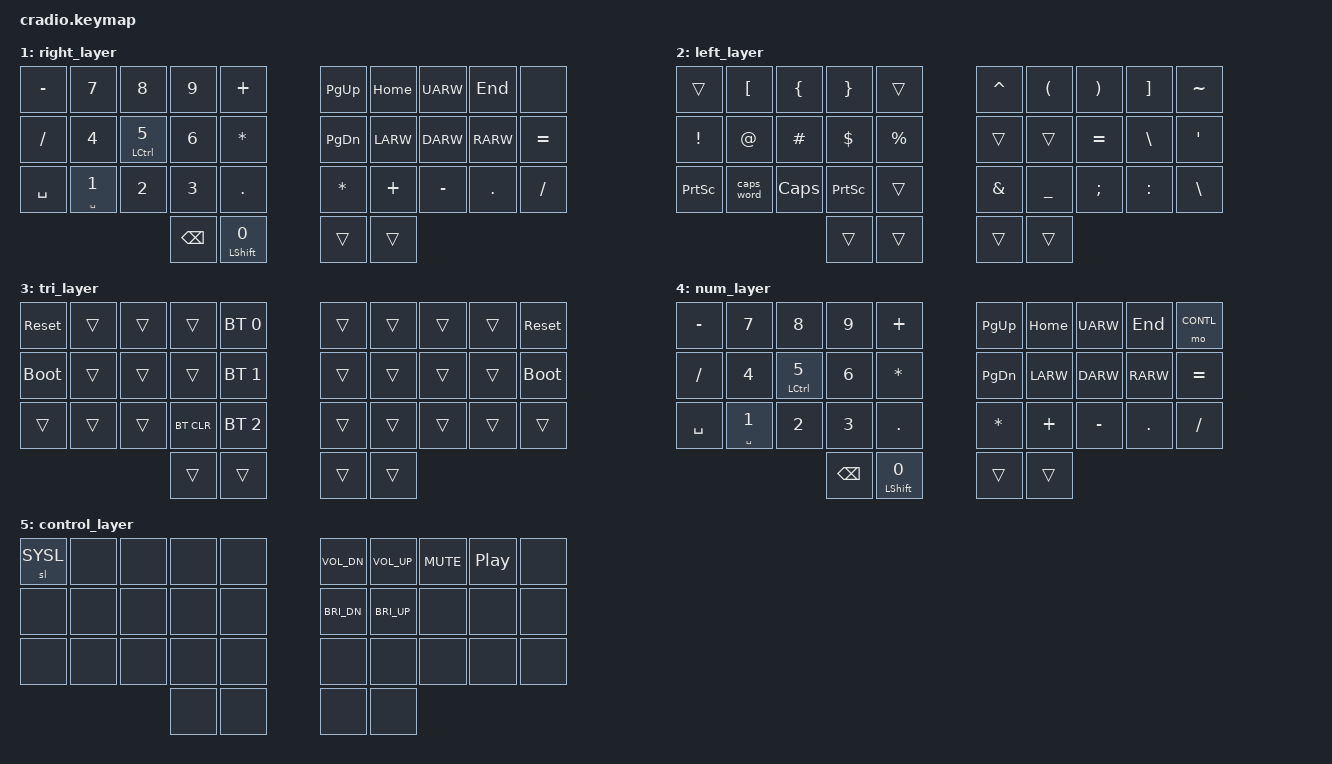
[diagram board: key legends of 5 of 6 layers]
// Copyright (c) 2022 The ZMK Contributors
// SPDX-License-Identifier: MIT

#include <behaviors.dtsi>
#include <dt-bindings/zmk/keys.h>
#include <dt-bindings/zmk/bt.h>

#include "../config/keypos_34keys.h"

#define DEFAULT 0
#define RIGHTL  1
#define LEFTL   2
#define SYSL    3
#define NUML    4
#define CONTL   5



// Home row mods macro
#define HRML(k1,k2,k3) &ht LALT k1  &ht LCTRL k2  &ht LGUI k3
#define HRMR(k1,k2,k3) &ht RGUI k1  &ht RCTRL k2  &ht RALT k3


&sk {  // sticky-key config
    release-after-ms = <600>;  // release after 0.6s
    quick-release;             // no double capitalization when rolling keys
};


/ {

    behaviors {
        ht: hold_tap {
            label = "hold_tap";
            compatible = "zmk,behavior-hold-tap";
            #binding-cells = <2>;
            flavor = "balanced";
            tapping-term-ms = <220>;
            quick-tap-ms = <150>;
            global-quick-tap;
            bindings = <&kp>, <&kp>;
        };
        pt: punctuation_tap {
            label = "punctuation_tap";
            compatible = "zmk,behavior-hold-tap";
            #binding-cells = <2>;
            flavor = "tap-preferred";
            tapping-term-ms = <180>;
            bindings = <&kp>, <&kp>;
        };


        ltt: layer_tap_with_rolling {
            label = "layer_tap_with_rolling";
            compatible = "zmk,behavior-hold-tap";
            #binding-cells = <2>;
            flavor = "tap-preferred";
            tapping-term-ms = <200>;
            quick-tap-ms = <125>;
            global-quick-tap;
            bindings = <&mo>, <&kp>;
        };


//      stt: sticky_tap {
//          label = "sticky_tap";
//          compatible = "zmk,behavior-hold-tap";
//          #binding-cells = <2>;
//          flavor = "hold-preferred";
//          tapping-term-ms = <90>;
//          bindings = <&kp>, <&sk>;
//      };
        swt: tab_switching {
            compatible = "zmk,behavior-mod-morph";
            label = "TAB_SWITCHING";
            #binding-cells = <0>;
            bindings = <&lt LEFTL BSPC>, <&kp TAB>;
            mods = <(MOD_LCTL|MOD_LALT)>;
            keep-mods = <(MOD_LCTL|MOD_LALT)>;
        };

    };

/*
    conditional_layers {
        compatible = "zmk,conditional-layers";
        tri_layer {
            if-layers = <RIGHTL LEFTL>;
            then-layer = <SYSL>;
        };
    };
*/
    
    
//  key position reference
//  ╭─────────────────────┬─────────────────────╮
//  │ LT4 LT3 LT2 LT1 LT0 │ RT0 RT1 RT2 RT3 RT4 │
//  │ LM4 LM3 LM2 LM1 LM0 │ RM0 RM1 RM2 RM3 RM4 │
//  │ LB4 LB3 LB2 LB1 LB0 │ RB0 RB1 RB2 RB3 RB4 │
//  ╰───────────╮ LH1 LH0 │ RH0 RH1 ╭───────────╯
//              ╰─────────┴─────────╯

     combos {
        compatible = "zmk,combos";
        
        combo_esc {
            timeout-ms = <50>;
            key-positions = <LT4 LT3>;
            bindings = <&kp ESC>;
        };
        combo_del {
            timeout-ms = <50>;
            key-positions = <LT3 LT2>;
            bindings = <&kp DEL>;
            layers = <DEFAULT NUML>;
        };
        combo_tab {
            timeout-ms = <45>;
            key-positions = <LM4 LM3>;
            bindings = <&kp TAB>;
            layers = <DEFAULT NUML RIGHTL>;
        };
         combo_enter_r {
            timeout-ms = <35>;
            key-positions = <RM2 RM3>;
            bindings = <&kp ENTER>;
        };
         combo_enter_l {
            timeout-ms = <35>;
            key-positions = <LM2 LM3>;
            bindings = <&ht LC(S) ENTER>;
        };
        combo_word_backspace {
            timeout-ms = <75>;
            key-positions = <LH1 RH1>;
            bindings = <&macro_word_bsp>;
            layers = <DEFAULT NUML>;
        };
        combo_word_delete {
            timeout-ms = <50>;
            key-positions = <LH0 RH0>;
            bindings = <&kp LC(DEL)>;
            layers = <DEFAULT>;
        };
        combo_equal {
            timeout-ms = <50>;
            key-positions = <LT0 LT1>;
            bindings = <&kp EQUAL>;
            layers = <RIGHTL NUML>;
        };
        combo_quote {
            timeout-ms = <50>;
            key-positions = <LB0 LB1>;
            bindings = <&kp DQT>;
            layers = <RIGHTL NUML>;
        };
        combo_num_layer {
            timeout-ms = <50>;
            key-positions = <LM1 LM3>;
            bindings = <&tog NUML>;
            layers = <DEFAULT NUML>;
        };
        combo_ctrl_f {
            timeout-ms = <50>;
            key-positions = <LT2 LM2>;
            bindings = <&kp LC(F)>;
            layers = <DEFAULT NUML>;
        };
        combo_at {
            timeout-ms = <35>;
            key-positions = <LM4 LM1>;
            bindings = <&kp AT>;
            layers = <DEFAULT RIGHTL NUML>;
        };
        combo_next_tab {
            timeout-ms = <40>;
            key-positions = <LB2 LB1>;
            bindings = <&kp LC(TAB)>;
            layers = <DEFAULT>;
        };
        combo_previous_tab {
            timeout-ms = <40>;
            key-positions = <LB3 LB2>;
            bindings = <&kp LC(LS(TAB))>;
            layers = <DEFAULT>;
        };
        combo_ctrl_x {
            timeout-ms = <50>;
            key-positions = <LT0 LT1>;
            bindings = <&kp LC(X)>;
            layers = <DEFAULT>;
        };
        combo_ctrl_c {
            timeout-ms = <50>;
            key-positions = <LM0 LM1>;
            bindings = <&kp LC(C)>;
            layers = <DEFAULT>;
        };
        combo_ctrl_v {
            timeout-ms = <50>;
            key-positions = <LB0 LB1>;
            bindings = <&kp LC(V)>;
            layers = <DEFAULT>;
        };

    };


    macros {
        macro_word_bsp: macro_word_bsp {
            label = "ZM_macro_word_backspace";
            compatible = "zmk,behavior-macro";
            #binding-cells = <0>;
            bindings
                = <&kp LS(LC(LARW))>
                , <&kp BSPC>
                ;
        };
    };
    
    keymap {
        compatible = "zmk,keymap";
        default_layer {
            bindings = <
        //╭──────────┬──────────┬──────────┬──────────┬──────────╮   ╭──────────┬──────────┬──────────┬──────────┬──────────╮
        //│  Q       │  W       │  F       │  P       │  G       │   │  J       │  L       │  U       │  Y       │  '       │
            &kp Q      &kp W      &kp F      &kp P      &kp G          &kp J      &kp L      &kp U      &kp Y      &ltt CONTL APOS
        //├──────────┼──────────┼──────────┼──────────┼──────────┤   ├──────────┼──────────┼──────────┼──────────┼──────────┤
        //│  A       │  R       │  S       │  T       │  D       │   │  H       │  N       │  E       │  I       │  O       │
            &kp A      HRML(R,         S,         T)     &kp D         &kp H      HRMR(N,        E,         I)     &kp O
        //├──────────┼──────────┼──────────┼──────────┼──────────┤   ├──────────┼──────────┼──────────┼──────────┼──────────┤
        //│  Z       │  X       │  C       │  V       │  B       │   │  K       │  M       │ ,        │ .        │ / ?      │
            &kp Z      &pt Z X    &kp C      &kp V      &kp B          &kp K      &kp M      &kp COMMA  &kp DOT    &pt EXCL FSLH
        //╰──────────┴──────────┴──────────┼──────────┼──────────┤   ├──────────┼──────────┼──────────┴──────────┴──────────╯
        //                                 |          |          |   |          |          |
                                             &swt       &kp LSHIFT     &key_repeat &lt RIGHTL SPACE
        //                                 ╰──────────┴──────────╯   ╰──────────┴──────────╯
            >;
        };

        right_layer {
            bindings = <
        //╭──────────┬──────────┬──────────┬──────────┬──────────╮   ╭──────────┬──────────┬──────────┬──────────┬──────────╮
        //│ -        │  7       │  8       │  9       │  +       │   │ PAGE UP  │  HOME    │  UP      │ END      │          │
            &kp MINUS  &kp N7     &kp N8     &kp N9     &kp PLUS       &kp PG_UP  &kp HOME   &kp UARW   &kp END    &none
        //├──────────┼──────────┼──────────┼──────────┼──────────┤   ├──────────┼──────────┼──────────┼──────────┼──────────┤
        //│ /        │  4       │  5       │  6       │  *       │   │ PAGE DN  │ LEFT     │ DOWN     │ RIGHT    │  =       │
            &kp FSLH   &kp N4  &ht LCTRL N5  &kp N6     &kp ASTRK      &kp PG_DN  &kp LARW   &kp DARW   &kp RARW   &kp EQUAL
        //├──────────┼──────────┼──────────┼──────────┼──────────┤   ├──────────┼──────────┼──────────┼──────────┼──────────┤
        //│          │  1       │  2       │  3       │  .       │   │ *        │  +       │  -       │  .       │  /       │
          &kp SPACE  &pt SPACE N1 &kp N2     &kp N3     &kp DOT        &kp ASTRK  &kp PLUS   &kp MINUS  &kp DOT    &kp SLASH
        //╰──────────┴──────────┴──────────┼──────────┼──────────┤   ├──────────┼──────────┼──────────┴──────────┴──────────╯
        //                                 |          |  0       |   |          |          |
                                             &kp BSPC   &ht LSHIFT N0  &trans     &trans
        //                                 ╰──────────┴──────────╯   ╰──────────┴──────────╯
            >;
        };

        left_layer {
            bindings = <
        //╭──────────┬──────────┬──────────┬──────────┬──────────╮   ╭──────────┬──────────┬──────────┬──────────┬──────────╮
        //│          │  [       │  {       │  }       │          │   │  ^       │  (       │  )       │  ]       │  ~       │
            &trans     &kp LBKT   &kp LBRC   &kp RBRC   &trans         &kp CARET  &kp LPAR   &kp RPAR   &kp RBKT   &kp TILDE
        //├──────────┼──────────┼──────────┼──────────┼──────────┤   ├──────────┼──────────┼──────────┼──────────┼──────────┤
        //│  !       │  @       │  #       │  $       │  %       │   │          │          │  =       │  \       │  '       │
            &kp EXCL   &kp AT     &kp HASH   &kp DLLR   &kp PRCNT      &trans     &trans     &kp EQUAL  &kp BSLH   &kp APOS
        //├──────────┼──────────┼──────────┼──────────┼──────────┤   ├──────────┼──────────┼──────────┼──────────┼──────────┤
        //│  PSCRN   │CAPS WORD │CAPS LOCK │  PSCRN   │          │   │  &       │  _       │  ;       │  :       │  \       │
            &kp PSCRN  &caps_word &kp CAPS   &kp PSCRN  &trans         &kp AMPS   &kp UNDER  &kp SEMI   &kp COLON   &kp BSLH
        //╰──────────┴──────────┴──────────┼──────────┼──────────┤   ├──────────┼──────────┼──────────┴──────────┴──────────╯
        //                                 |          |          |   |          |          |
                                             &trans     &trans         &trans     &trans
        //                                 ╰──────────┴──────────╯   ╰──────────┴──────────╯
            >;
        };

        tri_layer {
            bindings = <
        //╭──────────┬──────────┬──────────┬──────────┬──────────╮   ╭──────────┬──────────┬──────────┬──────────┬──────────╮
        //│ RESET    │          │          │          │PROFILE 0 │   │          │          │          │          │  RESET   │
           &sys_reset  &trans     &trans     &trans    &bt BT_SEL 0    &trans     &trans     &trans     &trans    &sys_reset
        //├──────────┼──────────┼──────────┼──────────┼──────────┤   ├──────────┼──────────┼──────────┼──────────┼──────────┤
        //│BOOTLOADER│          │          │          │PROFILE 1 │   │          │          │          │          │BOOTLOADER│
          &bootloader  &trans     &trans     &trans    &bt BT_SEL 1    &trans     &trans     &trans     &trans    &bootloader
        //├──────────┼──────────┼──────────┼──────────┼──────────┤   ├──────────┼──────────┼──────────┼──────────┼──────────┤
        //│          │          │          │ CLEAR BT │PROFILE 2 │   │          │          │          │          │          │
            &trans     &trans     &trans    &bt BT_CLR &bt BT_SEL 2    &trans     &trans     &trans     &trans     &trans
        //╰──────────┴──────────┴──────────┼──────────┼──────────┤   ├──────────┼──────────┼──────────┴──────────┴──────────╯
        //                                 |          |          |   |          |          |
                                             &trans     &trans         &trans     &trans
        //                                 ╰──────────┴──────────╯   ╰──────────┴──────────╯
            >;
        };
        
        num_layer {
            bindings = <
        //╭──────────┬──────────┬──────────┬──────────┬──────────╮   ╭──────────┬──────────┬──────────┬──────────┬──────────╮
        //│  -       │  7       │  8       │  9       │  +       │   │ PAGE UP  │  HOME    │  UP      │ END      │          │
            &kp MINUS  &kp N7     &kp N8     &kp N9     &kp PLUS       &kp PG_UP  &kp HOME   &kp UARW   &kp END    &mo CONTL
        //├──────────┼──────────┼──────────┼──────────┼──────────┤   ├──────────┼──────────┼──────────┼──────────┼──────────┤
        //│  /       │  4       │  5       │  6       │  *       │   │ PAGE DN  │ LEFT     │ DOWN     │ RIGHT    │  =       │
            &kp SLASH  &kp N4  &ht LCTRL N5  &kp N6     &kp ASTRK      &kp PG_DN  &kp LARW   &kp DARW   &kp RARW   &kp EQUAL
        //├──────────┼──────────┼──────────┼──────────┼──────────┤   ├──────────┼──────────┼──────────┼──────────┼──────────┤
        //│          │  1       │  2       │  3       │ .        │   │ *        │  +       │  -       │  .       │  /       │
          &kp SPACE  &pt SPACE N1 &kp N2     &kp N3     &kp DOT        &kp ASTRK  &kp PLUS   &kp MINUS  &kp DOT    &kp SLASH
        //╰──────────┴──────────┴──────────┼──────────┼──────────┤   ├──────────┼──────────┼──────────┴──────────┴──────────╯
        //                                 |          |          |   |          |          |
                                             &kp BSPC   &ht LSHIFT N0  &trans     &trans
        //                                 ╰──────────┴──────────╯   ╰──────────┴──────────╯
            >;
        };
        
        control_layer {
            bindings = <
        //╭──────────┬──────────┬──────────┬──────────┬──────────╮   ╭──────────┬──────────┬──────────┬──────────┬──────────╮
        //│          │          │          │          │          │   │          │          │          │          │          │
            &sl SYSL   &none      &none      &none      &none      &kp C_VOL_DN &kp C_VOL_UP &kp C_MUTE &kp C_PP   &none
        //├──────────┼──────────┼──────────┼──────────┼──────────┤   ├──────────┼──────────┼──────────┼──────────┼──────────┤
        //│          │          │          │          │          │   │          │          │          │          │          │
            &none      &none      &none      &none      &none      &kp C_BRI_DN  &kp C_BRI_UP &none     &none      &none 
        //├──────────┼──────────┼──────────┼──────────┼──────────┤   ├──────────┼──────────┼──────────┼──────────┼──────────┤
        //│          │          │          │          │          │   │          │          │          │          │          │
            &none      &none      &none      &none      &none          &none      &none      &none      &none      &none 
        //╰──────────┴──────────┴──────────┼──────────┼──────────┤   ├──────────┼──────────┼──────────┴──────────┴──────────╯
        //                                 |          |          |   |          |          |
                                             &none      &none          &none      &none
        //                                 ╰──────────┴──────────╯   ╰──────────┴──────────╯
            >;
        };
    };
};
